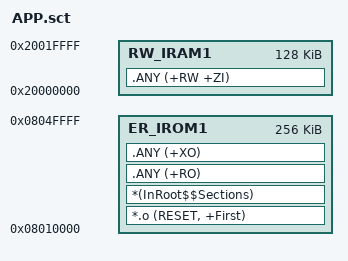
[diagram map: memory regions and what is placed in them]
; *************************************************************
; *** Scatter-Loading Description File generated by uVision ***
; *************************************************************

LR_IROM1 0x08010000 0x00040000  {    ; load region size_region
  ER_IROM1 0x08010000 0x00040000  {  ; load address = execution address
   *.o (RESET, +First)
   *(InRoot$$Sections)
   .ANY (+RO)
   .ANY (+XO)
  }
  ; 最后的 16 字节（0x0804FFF0～0x0804FFFF）留给魔数/版本，不分配
  RW_IRAM1 0x20000000 0x00020000  {  ; RW data
   .ANY (+RW +ZI)
  }
}

